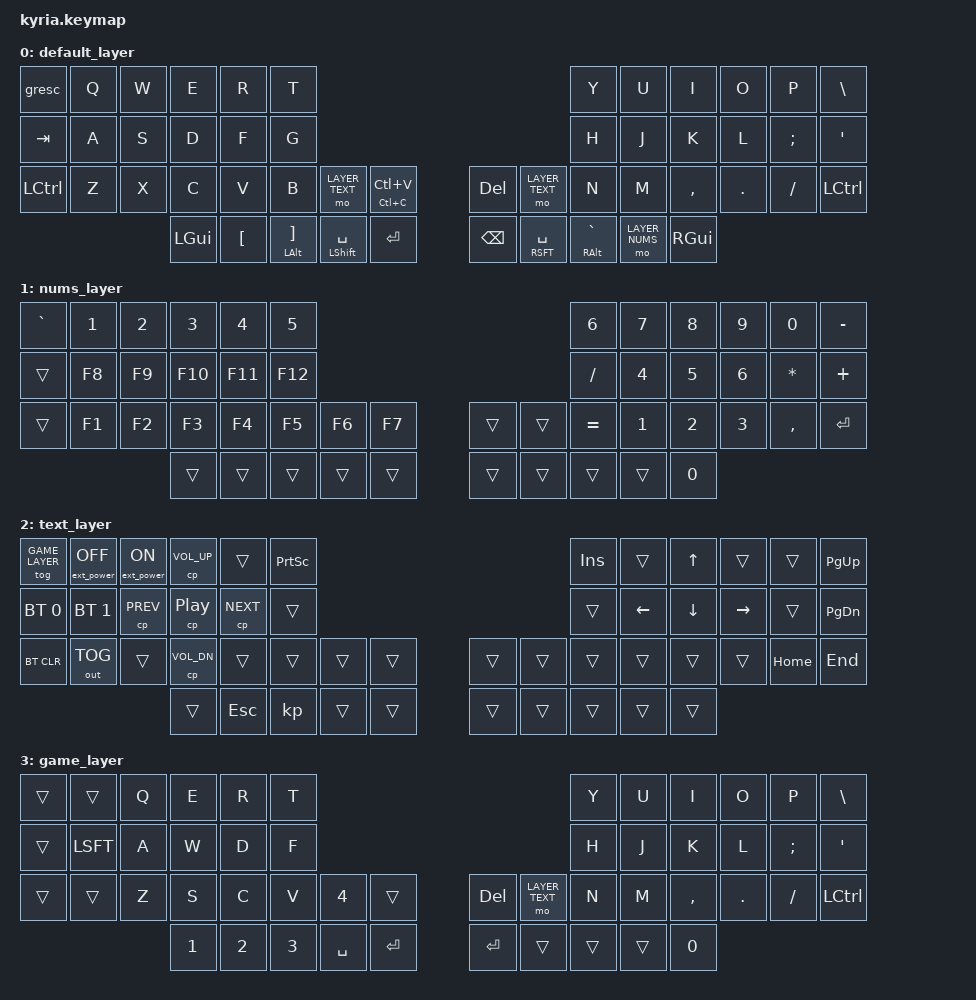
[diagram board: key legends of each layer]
#define DEFAULT 0
// ---------------------------------------------------------------------------------------------------------------------------------
// | ESC  |  Q  |  W  |  E   |  R  |  T    |                                                      |    Y    |   U   |  I    |  O   |   P   |   \  |
// | TAB  |  A  |  S  |  D   |  F  |  G    |                                                      |    H    |   J   |  K    |  L   |   ;   |   '  |
// | CTRL |  Z  |  X  |  C   |  V  |  B    |  *TEXT        |  Copy/Paste  |      |  DEL  |  *TEXT        |    N    |   M   |  ,    |  .   |   /   | CTRL |
//                    | GUI  |  [  | ][alt]|  SPACE [shift]|  RET         |      |  BKSP |  SPACE [shift]|  ` [alt]| *NUMS | R-ALT |

#define LAYER_NUMS 1 
// ---------------------------------------------------------------------------------------------------------------------------------
// |       |   1 |   2 |   3  |   4  |   5  |                                        |  6  |   7   |  8   |  9   |   0   |  -    |
// |       |  F8 |  F9 |  F10 |  F11 |  F12 |                                        |  /  |   4   |  5   |  6   |   *   |  +    |
// |       |  F1 |  F2 |  F3  |  F4  |  F5  |   F6   |  F7   |      |       |        |  =  |   1   |  2   |  3   |   ,   |  RET  |
//                     |      |      |      |        |       |      |       |        |     |       |  0   |

#define LAYER_TEXT 2
// ---------------------------------------------------------------------------------------------------------------------------------
// |       |     |      | V UP    |       |      |                                         |      |       |   ↑   |     |       |  PGUP |
// |       |     | Prev | PLAY    |  Next |      |                                         |      |   ←   |   ↓   |  →  |       |  PGDN |
// |       |     |      | V DOWN  |       |      |       |      |            |      |      |      |       |       |     |  HOME |  END  |
//                      |         |  ESC  |      |       |      |            |      |      |      |       |       |

#define GAME_LAYER 3
// ---------------------------------------------------------------------------------------------------------------------------------
// |       |     |      | V UP    |       |      |                                         | INS  |       |   ↑   |     |       |  PGUP |
// |       |     | Prev | PLAY    |  Next |      |                                         |      |   ←   |   ↓   |  →  |       |  PGDN |
// |       |     |      | V DOWN  |       |      |       |      |            |      |      |      |       |       |     |  HOME |  END  |
//                      |         |  ESC  |      |       |      |            |      |      |      |       |       |


#include <behaviors.dtsi>
#include <dt-bindings/zmk/keys.h>
#include <dt-bindings/zmk/bt.h>
#include <dt-bindings/zmk/outputs.h>
#include <dt-bindings/zmk/ext_power.h>


/ {
  behaviors {
        hm: homerow_mods {
            compatible = "zmk,behavior-hold-tap";
            label = "HOMEROW_MODS";
            #binding-cells = <2>;
            tapping_term_ms = <175>;
            flavor = "balanced";
            bindings = <&kp>, <&kp>;
        };
    };
        
	
	keymap {
		compatible = "zmk,keymap";

		default_layer {
			bindings = <
	&gresc  &kp Q &kp W &kp E &kp R &kp T                                                               &kp Y         &kp U          &kp I    &kp O   &kp P    &kp BSLH
	&kp TAB  &kp A &kp S &kp D &kp F &kp G                                                               &kp H         &kp J          &kp K    &kp L   &kp SEMI &kp SQT
	&kp LCTL &kp Z &kp X &kp C &kp V &kp B         &mo LAYER_TEXT   &mt LC(C)  LC(V)  &kp DEL  &mo LAYER_TEXT &kp N         &kp M          &kp CMMA &kp DOT &kp FSLH &kp LCTL 
	               &kp LGUI &kp LBKT &mt LALT RBKT &mt LSHFT SPACE   &kp RET       	 &kp BSPC &mt RSFT SPACE   &mt RALT GRAV &mo LAYER_NUMS &kp RGUI
			>;
		};

		nums_layer {
			bindings = <
	&kp GRAVE &kp N1 &kp N2 &kp N3 &kp N4 &kp N5                                           &kp N6  &kp N7  &kp N8    &kp N9   &kp N0    &kp MINUS  
	&trans   &kp F8    &kp F9    &kp F10   &kp F11   &kp F12                                             &kp SLASH   &kp N4  &kp N5    &kp N6   &kp ASTERISK     &kp PLUS  
	&trans   &kp F1    &kp F2    &kp F3    &kp F4    &kp F5    &kp F6  &kp F7         &trans    &trans   &kp EQUAL    &kp N1  &kp N2    &kp N3   &kp CMMA     &kp RET   
	                   &trans    &trans   &trans    &trans    &trans  &trans         &trans    &trans   &trans     &kp NUM_0     
			>;
		};
		
		text_layer {
			bindings = <
	&tog GAME_LAYER   &ext_power EP_OFF    &ext_power EP_ON     &cp C_VOL_UP   &trans     &kp PSCRN                                                 &kp INS   &trans    &kp UP   &trans    &trans    &kp PG_UP   
	&bt BT_SEL 0  &bt BT_SEL 1   &cp C_PREV &cp C_PLAY_PAUSE   &cp C_NEXT &trans                                                 &trans  &kp LEFT  &kp DOWN   &kp RIGHT  &trans    &kp PG_DN  
	&bt BT_CLR    &out OUT_TOG    &trans     &cp C_VOL_DN   &trans     &trans    &trans    &trans         &trans    &trans    &trans  &trans    &trans     &trans    &kp HOME  &kp END 
	                               &trans       &kp ESC    &kp       &trans    &trans         &trans    &trans    &trans  &trans    &trans     
			>; 
		 };
			
		game_layer {
			bindings = <
	&trans   &trans  &kp Q     &kp E    &kp R   &kp T                                             &kp Y         &kp U          &kp I    &kp O   &kp P    &kp BSLH
	&trans    &kp LSFT    &kp A   &kp W    &kp D   &kp F                                               &kp H         &kp J          &kp K    &kp L   &kp SCLN &kp QUOT
	&trans   &trans   &kp Z    &kp S    &kp C   &kp V    &kp NUM_4  &trans                &kp DEL  &mo LAYER_TEXT &kp N         &kp M          &kp CMMA &kp DOT &kp FSLH &kp LCTL   
	                   &kp NUM_1  &kp NUM_2    &kp NUM_3    &kp SPC    &kp RET  &kp RET          &trans    &trans   &trans     &kp NUM_0     
			>;	
                 
		};
	};
};
